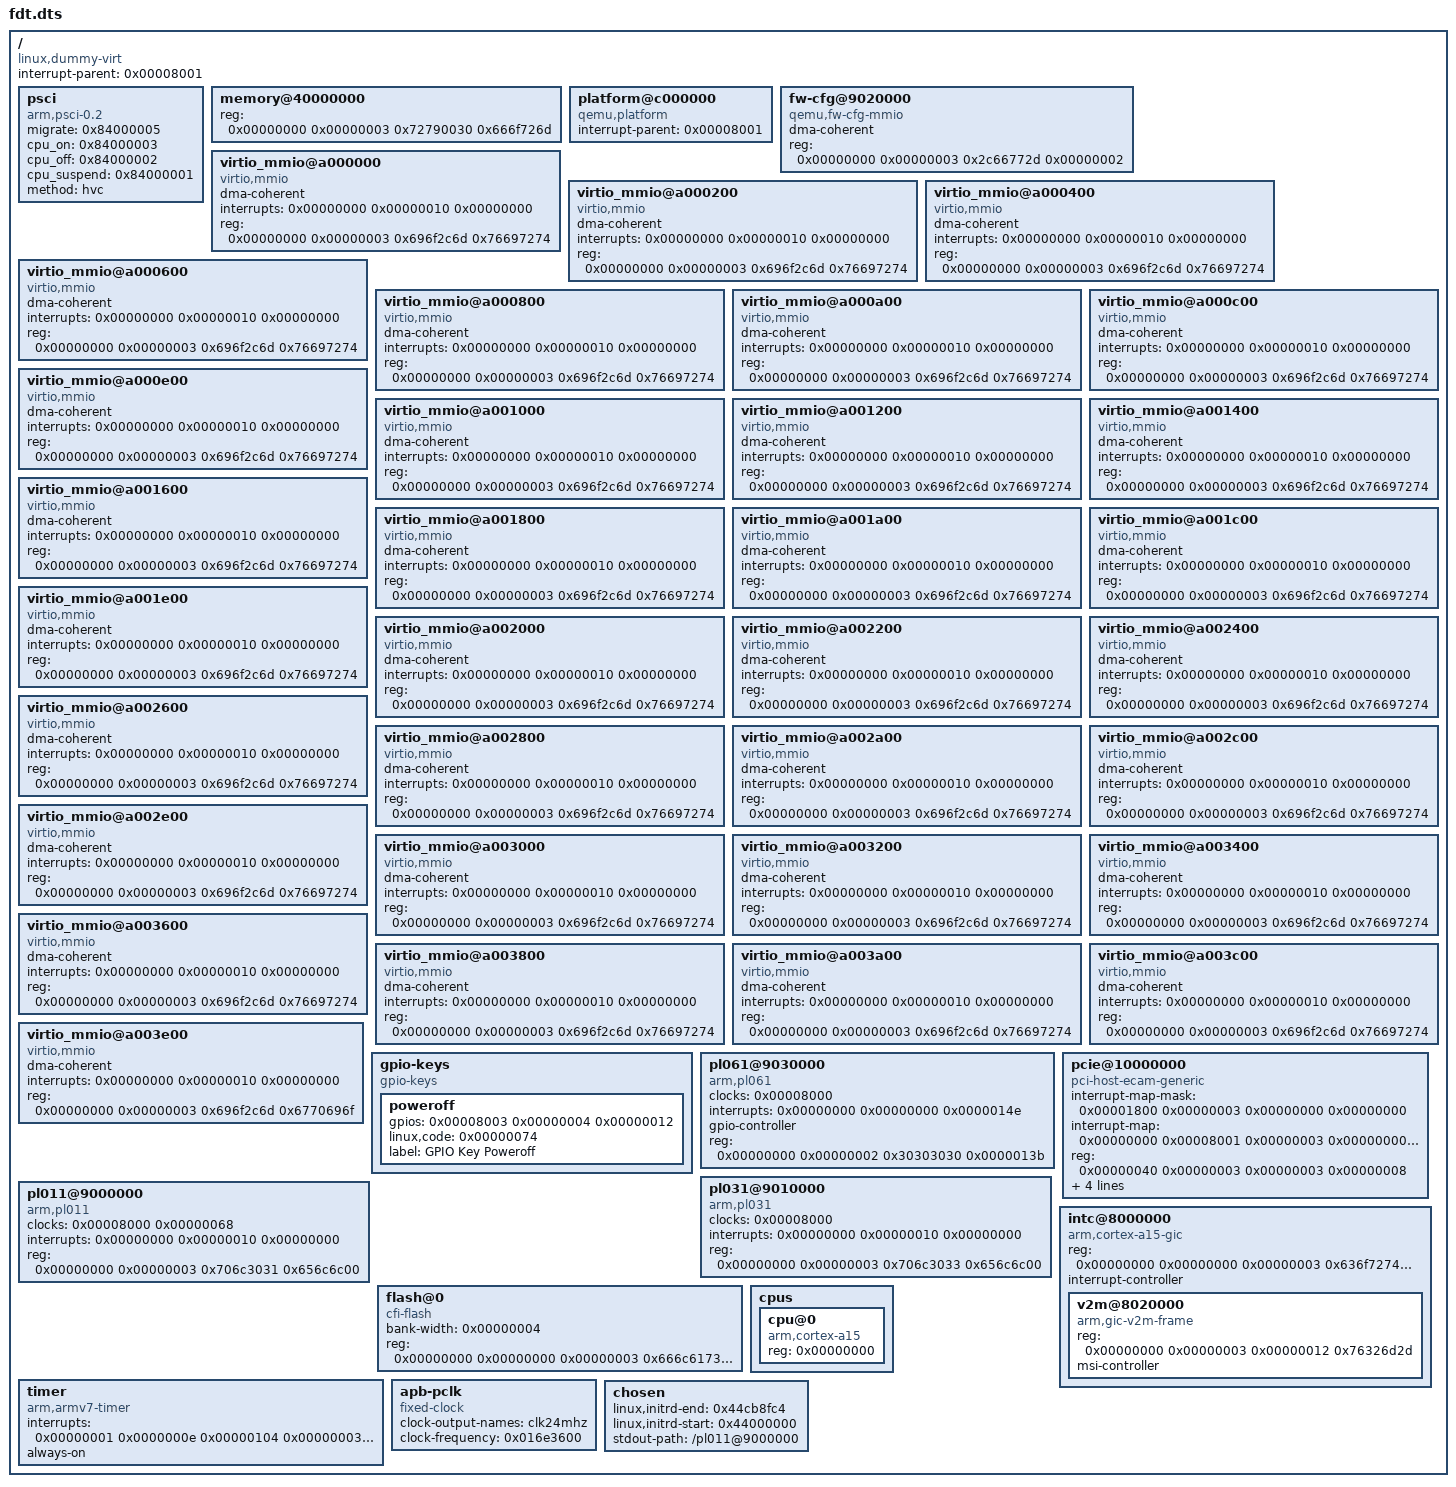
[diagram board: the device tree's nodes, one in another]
/dts-v1/;
// magic:		0xd00dfeed
// totalsize:		0x100000 (1048576)
// off_dt_struct:	0x40
// off_dt_strings:	0x1aa0
// off_mem_rsvmap:	0x30
// version:		17
// last_comp_version:	16
// boot_cpuid_phys:	0x0
// size_dt_strings:	0x1cf
// size_dt_struct:	0x1a60

/ {
    interrupt-parent = <0x00008001>;
    #size-cells = <0x00000002>;
    #address-cells = <0x00000002>;
    compatible = "linux,dummy-virt";
    psci {
        migrate = <0x84000005>;
        cpu_on = <0x84000003>;
        cpu_off = <0x84000002>;
        cpu_suspend = <0x84000001>;
        method = "hvc";
        compatible = "arm,psci-0.2", "arm,psci";
    };
    memory@40000000 {
        reg = <0x00000000 0x00000003 0x72790030 0x666f726d>;
        device_type = "memory";
    };
    platform@c000000 {
        interrupt-parent = <0x00008001>;
        ranges = <0x00000000 0x00000003 0x00000003 0x00000003>;
        #address-cells = <0x00000001>;
        #size-cells = <0x00000001>;
        compatible = "qemu,platform", "simple-bus";
    };
    fw-cfg@9020000 {
        dma-coherent;
        reg = <0x00000000 0x00000003 0x2c66772d 0x00000002>;
        compatible = "qemu,fw-cfg-mmio";
    };
    virtio_mmio@a000000 {
        dma-coherent;
        interrupts = <0x00000000 0x00000010 0x00000000>;
        reg = <0x00000000 0x00000003 0x696f2c6d 0x76697274>;
        compatible = "virtio,mmio";
    };
    virtio_mmio@a000200 {
        dma-coherent;
        interrupts = <0x00000000 0x00000010 0x00000000>;
        reg = <0x00000000 0x00000003 0x696f2c6d 0x76697274>;
        compatible = "virtio,mmio";
    };
    virtio_mmio@a000400 {
        dma-coherent;
        interrupts = <0x00000000 0x00000010 0x00000000>;
        reg = <0x00000000 0x00000003 0x696f2c6d 0x76697274>;
        compatible = "virtio,mmio";
    };
    virtio_mmio@a000600 {
        dma-coherent;
        interrupts = <0x00000000 0x00000010 0x00000000>;
        reg = <0x00000000 0x00000003 0x696f2c6d 0x76697274>;
        compatible = "virtio,mmio";
    };
    virtio_mmio@a000800 {
        dma-coherent;
        interrupts = <0x00000000 0x00000010 0x00000000>;
        reg = <0x00000000 0x00000003 0x696f2c6d 0x76697274>;
        compatible = "virtio,mmio";
    };
    virtio_mmio@a000a00 {
        dma-coherent;
        interrupts = <0x00000000 0x00000010 0x00000000>;
        reg = <0x00000000 0x00000003 0x696f2c6d 0x76697274>;
        compatible = "virtio,mmio";
    };
    virtio_mmio@a000c00 {
        dma-coherent;
        interrupts = <0x00000000 0x00000010 0x00000000>;
        reg = <0x00000000 0x00000003 0x696f2c6d 0x76697274>;
        compatible = "virtio,mmio";
    };
    virtio_mmio@a000e00 {
        dma-coherent;
        interrupts = <0x00000000 0x00000010 0x00000000>;
        reg = <0x00000000 0x00000003 0x696f2c6d 0x76697274>;
        compatible = "virtio,mmio";
    };
    virtio_mmio@a001000 {
        dma-coherent;
        interrupts = <0x00000000 0x00000010 0x00000000>;
        reg = <0x00000000 0x00000003 0x696f2c6d 0x76697274>;
        compatible = "virtio,mmio";
    };
    virtio_mmio@a001200 {
        dma-coherent;
        interrupts = <0x00000000 0x00000010 0x00000000>;
        reg = <0x00000000 0x00000003 0x696f2c6d 0x76697274>;
        compatible = "virtio,mmio";
    };
    virtio_mmio@a001400 {
        dma-coherent;
        interrupts = <0x00000000 0x00000010 0x00000000>;
        reg = <0x00000000 0x00000003 0x696f2c6d 0x76697274>;
        compatible = "virtio,mmio";
    };
    virtio_mmio@a001600 {
        dma-coherent;
        interrupts = <0x00000000 0x00000010 0x00000000>;
        reg = <0x00000000 0x00000003 0x696f2c6d 0x76697274>;
        compatible = "virtio,mmio";
    };
    virtio_mmio@a001800 {
        dma-coherent;
        interrupts = <0x00000000 0x00000010 0x00000000>;
        reg = <0x00000000 0x00000003 0x696f2c6d 0x76697274>;
        compatible = "virtio,mmio";
    };
    virtio_mmio@a001a00 {
        dma-coherent;
        interrupts = <0x00000000 0x00000010 0x00000000>;
        reg = <0x00000000 0x00000003 0x696f2c6d 0x76697274>;
        compatible = "virtio,mmio";
    };
    virtio_mmio@a001c00 {
        dma-coherent;
        interrupts = <0x00000000 0x00000010 0x00000000>;
        reg = <0x00000000 0x00000003 0x696f2c6d 0x76697274>;
        compatible = "virtio,mmio";
    };
    virtio_mmio@a001e00 {
        dma-coherent;
        interrupts = <0x00000000 0x00000010 0x00000000>;
        reg = <0x00000000 0x00000003 0x696f2c6d 0x76697274>;
        compatible = "virtio,mmio";
    };
    virtio_mmio@a002000 {
        dma-coherent;
        interrupts = <0x00000000 0x00000010 0x00000000>;
        reg = <0x00000000 0x00000003 0x696f2c6d 0x76697274>;
        compatible = "virtio,mmio";
    };
    virtio_mmio@a002200 {
        dma-coherent;
        interrupts = <0x00000000 0x00000010 0x00000000>;
        reg = <0x00000000 0x00000003 0x696f2c6d 0x76697274>;
        compatible = "virtio,mmio";
    };
    virtio_mmio@a002400 {
        dma-coherent;
        interrupts = <0x00000000 0x00000010 0x00000000>;
        reg = <0x00000000 0x00000003 0x696f2c6d 0x76697274>;
        compatible = "virtio,mmio";
    };
    virtio_mmio@a002600 {
        dma-coherent;
        interrupts = <0x00000000 0x00000010 0x00000000>;
        reg = <0x00000000 0x00000003 0x696f2c6d 0x76697274>;
        compatible = "virtio,mmio";
    };
    virtio_mmio@a002800 {
        dma-coherent;
        interrupts = <0x00000000 0x00000010 0x00000000>;
        reg = <0x00000000 0x00000003 0x696f2c6d 0x76697274>;
        compatible = "virtio,mmio";
    };
    virtio_mmio@a002a00 {
        dma-coherent;
        interrupts = <0x00000000 0x00000010 0x00000000>;
        reg = <0x00000000 0x00000003 0x696f2c6d 0x76697274>;
        compatible = "virtio,mmio";
    };
    virtio_mmio@a002c00 {
        dma-coherent;
        interrupts = <0x00000000 0x00000010 0x00000000>;
        reg = <0x00000000 0x00000003 0x696f2c6d 0x76697274>;
        compatible = "virtio,mmio";
    };
    virtio_mmio@a002e00 {
        dma-coherent;
        interrupts = <0x00000000 0x00000010 0x00000000>;
        reg = <0x00000000 0x00000003 0x696f2c6d 0x76697274>;
        compatible = "virtio,mmio";
    };
    virtio_mmio@a003000 {
        dma-coherent;
        interrupts = <0x00000000 0x00000010 0x00000000>;
        reg = <0x00000000 0x00000003 0x696f2c6d 0x76697274>;
        compatible = "virtio,mmio";
    };
    virtio_mmio@a003200 {
        dma-coherent;
        interrupts = <0x00000000 0x00000010 0x00000000>;
        reg = <0x00000000 0x00000003 0x696f2c6d 0x76697274>;
        compatible = "virtio,mmio";
    };
    virtio_mmio@a003400 {
        dma-coherent;
        interrupts = <0x00000000 0x00000010 0x00000000>;
        reg = <0x00000000 0x00000003 0x696f2c6d 0x76697274>;
        compatible = "virtio,mmio";
    };
    virtio_mmio@a003600 {
        dma-coherent;
        interrupts = <0x00000000 0x00000010 0x00000000>;
        reg = <0x00000000 0x00000003 0x696f2c6d 0x76697274>;
        compatible = "virtio,mmio";
    };
    virtio_mmio@a003800 {
        dma-coherent;
        interrupts = <0x00000000 0x00000010 0x00000000>;
        reg = <0x00000000 0x00000003 0x696f2c6d 0x76697274>;
        compatible = "virtio,mmio";
    };
    virtio_mmio@a003a00 {
        dma-coherent;
        interrupts = <0x00000000 0x00000010 0x00000000>;
        reg = <0x00000000 0x00000003 0x696f2c6d 0x76697274>;
        compatible = "virtio,mmio";
    };
    virtio_mmio@a003c00 {
        dma-coherent;
        interrupts = <0x00000000 0x00000010 0x00000000>;
        reg = <0x00000000 0x00000003 0x696f2c6d 0x76697274>;
        compatible = "virtio,mmio";
    };
    virtio_mmio@a003e00 {
        dma-coherent;
        interrupts = <0x00000000 0x00000010 0x00000000>;
        reg = <0x00000000 0x00000003 0x696f2c6d 0x6770696f>;
        compatible = "virtio,mmio";
    };
    gpio-keys {
        #address-cells = <0x00000001>;
        #size-cells = <0x00000000>;
        compatible = "gpio-keys";
        poweroff {
            gpios = <0x00008003 0x00000004 0x00000012>;
            linux,code = <0x00000074>;
            label = "GPIO Key Poweroff";
        };
    };
    pl061@9030000 {
        phandle = <0x00008003>;
        clock-names = "apb_pclk";
        clocks = <0x00008000>;
        interrupts = <0x00000000 0x00000000 0x0000014e>;
        gpio-controller;
        #gpio-cells = <0x00000002>;
        compatible = "arm,pl061", "arm,primecell";
        reg = <0x00000000 0x00000002 0x30303030 0x0000013b>;
    };
    pcie@10000000 {
        interrupt-map-mask = <0x00001800 0x00000003 0x00000000 0x00000000>;
        interrupt-map = <0x00000000 0x00008001 0x00000003 0x00000000 0x00000000 0x00000000 0x00008001 0x00000005 0x00000000 0x00000000 0x00000800 0x00008001 0x00000004 0x00000000 0x00000000 0x00000800 0x00008001 0x00000006 0x00000000 0x00000000 0x00001000 0x00008001 0x00000005 0x00000000 0x00000000 0x00001000 0x00008001 0x00000003 0x00000000 0x00000000 0x00001800 0x00008001 0x00000006 0x00000000 0x00000000 0x00001800 0x00008001 0x00000004 0x00000000 0x00000000 0x00000003 0x00000003 0x00000000 0x00000000 0x10000000 0x2eff0000 0x00000080 0x00000003 0x10000000 0x00000004 0x00000000 0x0000010b 0x00000004 0x00000004 0x00000004 0x00000004 0x00000016 0x2d656361 0x00000002 0x31303030 0x000000e2 0x00000003 0x00000003 0x00000002 0x0000007f 0x00001000 0x61726d2c 0x696d6563 0x706c3031 0x00000003 0x636c6b00 0x00000003 0x00008000 0x00000000 0x00000010 0x00000000 0x00000000 0x6d2c7072 0x00000001 0x00000000 0x00008001 0x00000000 0x00000000 0x00000003 0x636f7274 0x00000003 0x00000004 0x00000004 0x00000000 0x0000009f 0x38303230 0x00000056 0x0000007f 0x00001000 0x00000003 0x6769632d 0x00000002 0x68403000 0x00000004 0x00000000 0x00000000 0x00000003 0x666c6173 0x63707573 0x0000001a 0x0000000b 0x30000000 0x00000000 0x61726d2c 0x00000003 0x00000002 0x72000000 0x00000001 0x0000000e 0x00000104 0x00000003 0x00000010 0x372d7469 0x6170622d 0x00000004 0x00000009 0x00000004 0x016e3600 0x00000000 0x66697865 0x00000001 0x00000004 0x00000004 0x0000000f 0x30303030 0x00000009 0x61646472 0x697a652d 0x2d63656c 0x7175656e 0x7075742d 0x6500616c 0x72727570 0x70650072 0x6800696e 0x6e740023 0x6c6c7300 0x6e74726f 0x6d73692d 0x6c6f636b 0x73007374 0x6e75782c 0x75732d72 0x6572656e 0x00696e74 0x6e746572 0x6b002367 0x696f2d63 0x62656c00 0x70696f73 0x642d7374 0x69747264 0x6370755f 0x6f666600 0x74650000>;
        #interrupt-cells = <0x00000001>;
        ranges = <0x01000000 0x3eff0000 0x00000000 0x00000000 0x00000000 0x00000000 0x00000040 0x00000003 0x00000003 0x00000008 0x00000003 0x00000003 0x00000003 0x00000003 0x00000003 0x686f7374 0x630000e2 0x31403930 0x00000009 0x0000000c 0x00008000>;
        reg = <0x00000040 0x00000003 0x00000003 0x00000008>;
        msi-parent = <0x00008002>;
        dma-coherent;
        bus-range = <0x00000000 0x000000fa>;
        linux,pci-domain = <0x00000000>;
        #size-cells = <0x00000002>;
        #address-cells = <0x00000003>;
        device_type = "pci";
        compatible = "pci-host-ecam-generic";
    };
    pl031@9010000 {
        clock-names = "apb_pclk";
        clocks = <0x00008000>;
        interrupts = <0x00000000 0x00000010 0x00000000>;
        reg = <0x00000000 0x00000003 0x706c3033 0x656c6c00>;
        compatible = "arm,pl031", "arm,primecell";
    };
    pl011@9000000 {
        clock-names = "uartclk", "apb_pclk";
        clocks = <0x00008000 0x00000068>;
        interrupts = <0x00000000 0x00000010 0x00000000>;
        reg = <0x00000000 0x00000003 0x706c3031 0x656c6c00>;
        compatible = "arm,pl011", "arm,primecell";
    };
    intc@8000000 {
        phandle = <0x00008001>;
        reg = <0x00000000 0x00000000 0x00000003 0x636f7274 0x00000003 0x00000004 0x00000004 0x00000000>;
        compatible = "arm,cortex-a15-gic";
        ranges;
        #size-cells = <0x00000002>;
        #address-cells = <0x00000002>;
        interrupt-controller;
        #interrupt-cells = <0x00000003>;
        v2m@8020000 {
            phandle = <0x00008002>;
            reg = <0x00000000 0x00000003 0x00000012 0x76326d2d>;
            msi-controller;
            compatible = "arm,gic-v2m-frame";
        };
    };
    flash@0 {
        bank-width = <0x00000004>;
        reg = <0x00000000 0x00000000 0x00000003 0x666c6173 0x63707573 0x0000001a 0x0000000b 0x30000000>;
        compatible = "cfi-flash";
    };
    cpus {
        #size-cells = <0x00000000>;
        #address-cells = <0x00000001>;
        cpu@0 {
            reg = <0x00000000>;
            compatible = "arm,cortex-a15";
            device_type = "cpu";
        };
    };
    timer {
        interrupts = <0x00000001 0x0000000e 0x00000104 0x00000003 0x00000010 0x372d7469 0x6170622d 0x00000004 0x00000009 0x00000004 0x016e3600 0x00000000>;
        always-on;
        compatible = "arm,armv7-timer";
    };
    apb-pclk {
        phandle = <0x00008000>;
        clock-output-names = "clk24mhz";
        clock-frequency = <0x016e3600>;
        #clock-cells = <0x00000000>;
        compatible = "fixed-clock";
    };
    chosen {
        linux,initrd-end = <0x44cb8fc4>;
        linux,initrd-start = <0x44000000>;
        stdout-path = "/pl011@9000000";
    };
};
